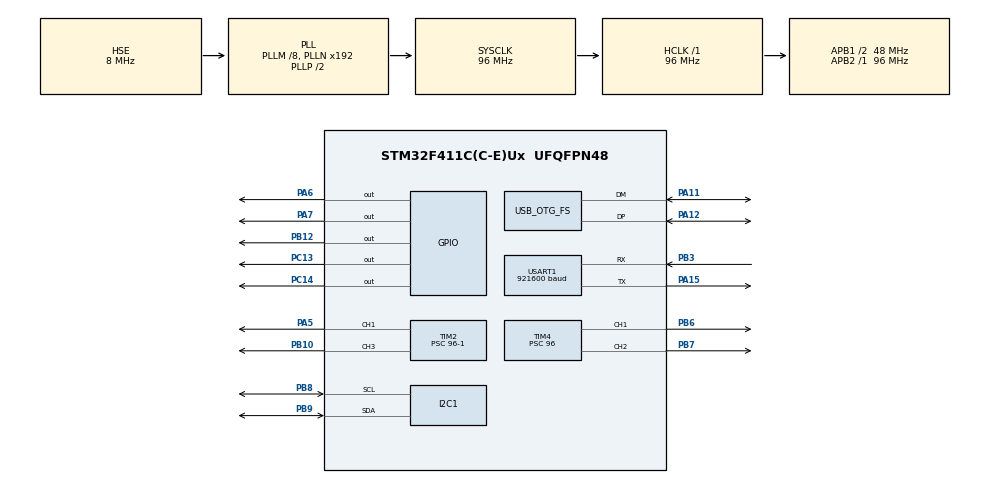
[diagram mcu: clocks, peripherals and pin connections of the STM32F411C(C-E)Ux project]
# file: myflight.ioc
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FREERTOS.Tasks01=defaultTask,8,128,StartDefaultTask,As weak,NULL,Dynamic,NULL,NULL;TaskSensorMotor,40,1024,StartTaskSensorMotor,As weak,NULL,Dynamic,NULL,NULL;TaskDebug,8,512,StartTaskDebug,As weak,NULL,Dynamic,NULL,NULL;TaskLED,8,512,StartTaskLED,As weak,NULL,Dynamic,NULL,NULL;TaskMessage,48,512,StartTaskMessage,As weak,NULL,Dynamic,NULL,NULL
FREERTOS.configENABLE_FPU=1
I2C1.I2C_Mode=I2C_Standard
Mcu.Family=STM32F4
Mcu.Name=STM32F411C(C-E)Ux
Mcu.Package=UFQFPN48
NVIC.OTG_FS_IRQn=true\:5\:0\:false\:false\:true\:true\:false\:true
NVIC.PriorityGroup=NVIC_PRIORITYGROUP_4
NVIC.TIM1_UP_TIM10_IRQn=true\:0\:0\:false\:false\:true\:false\:false\:true
NVIC.TimeBase=TIM1_UP_TIM10_IRQn
NVIC.TimeBaseIP=TIM10
NVIC.USART1_IRQn=true\:5\:0\:false\:false\:true\:true\:true\:true
PA11.Mode=Device_Only
PA11.Signal=USB_OTG_FS_DM
PA12.Mode=Device_Only
PA12.Signal=USB_OTG_FS_DP
PA15.Mode=Asynchronous
PA15.Signal=USART1_TX
PA5.Signal=S_TIM2_CH1_ETR
PA6.GPIO_ModeDefaultOutputPP=GPIO_MODE_OUTPUT_PP
PA6.GPIO_PuPd=GPIO_PULLDOWN
PA6.GPIO_Speed=GPIO_SPEED_FREQ_VERY_HIGH
PA6.PinState=GPIO_PIN_SET
PA6.Signal=GPIO_Output
PA7.GPIO_ModeDefaultOutputPP=GPIO_MODE_OUTPUT_PP
PA7.GPIO_PuPd=GPIO_PULLDOWN
PA7.GPIO_Speed=GPIO_SPEED_FREQ_VERY_HIGH
PA7.PinState=GPIO_PIN_SET
PA7.Signal=GPIO_Output
PB10.Signal=S_TIM2_CH3
PB12.GPIO_ModeDefaultOutputPP=GPIO_MODE_OUTPUT_PP
PB12.GPIO_PuPd=GPIO_PULLDOWN
PB12.GPIO_Speed=GPIO_SPEED_FREQ_VERY_HIGH
PB12.PinState=GPIO_PIN_RESET
PB12.Signal=GPIO_Output
PB3.Mode=Asynchronous
PB3.Signal=USART1_RX
PB6.Signal=S_TIM4_CH1
PB7.Signal=S_TIM4_CH2
PB8.Mode=I2C
PB8.Signal=I2C1_SCL
PB9.Mode=I2C
PB9.Signal=I2C1_SDA
PC13-ANTI_TAMP.GPIO_ModeDefaultOutputPP=GPIO_MODE_OUTPUT_PP
PC13-ANTI_TAMP.GPIO_PuPd=GPIO_PULLDOWN
PC13-ANTI_TAMP.PinState=GPIO_PIN_SET
PC13-ANTI_TAMP.Signal=GPIO_Output
PC14-OSC32_IN.GPIO_ModeDefaultOutputPP=GPIO_MODE_OUTPUT_PP
PC14-OSC32_IN.GPIO_PuPd=GPIO_PULLDOWN
PC14-OSC32_IN.PinState=GPIO_PIN_SET
PC14-OSC32_IN.Signal=GPIO_Output
PH0\ -\ OSC_IN.Mode=HSE-External-Oscillator
PH0\ -\ OSC_IN.Signal=RCC_OSC_IN
PH1\ -\ OSC_OUT.Mode=HSE-External-Oscillator
PH1\ -\ OSC_OUT.Signal=RCC_OSC_OUT
ProjectManager.HeapSize=0x3000
ProjectManager.StackSize=0x800
ProjectManager.TargetToolchain=MDK-ARM V5.27
RCC.48MHZClocksFreq_Value=48000000
RCC.AHBFreq_Value=96000000
RCC.APB1CLKDivider=RCC_HCLK_DIV2
RCC.APB1Freq_Value=48000000
RCC.APB1TimFreq_Value=96000000
RCC.APB2Freq_Value=96000000
RCC.APB2TimFreq_Value=96000000
RCC.CortexFreq_Value=96000000
RCC.HCLKFreq_Value=96000000
RCC.HSE_VALUE=8000000
RCC.HSI_VALUE=16000000
RCC.LSE_VALUE=32768
RCC.PLLM=8
RCC.SYSCLKFreq_VALUE=96000000
RCC.SYSCLKSource=RCC_SYSCLKSOURCE_PLLCLK
RCC.VCOOutputFreq_Value=192000000
SH.S_TIM2_CH1_ETR.0=TIM2_CH1,PWM Generation1 CH1
SH.S_TIM2_CH3.0=TIM2_CH3,PWM Generation3 CH3
SH.S_TIM4_CH1.0=TIM4_CH1,PWM Generation1 CH1
SH.S_TIM4_CH2.0=TIM4_CH2,PWM Generation2 CH2
TIM2.Channel-PWM\ Generation1\ CH1=TIM_CHANNEL_1
TIM2.Channel-PWM\ Generation3\ CH3=TIM_CHANNEL_3
TIM2.Period=1000
TIM2.Prescaler=96-1
TIM4.Channel-PWM\ Generation1\ CH1=TIM_CHANNEL_1
TIM4.Channel-PWM\ Generation2\ CH2=TIM_CHANNEL_2
TIM4.Period=1000
TIM4.Prescaler=96
USART1.BaudRate=921600
USART1.VirtualMode=VM_ASYNC
USB_DEVICE.CLASS_NAME_FS=CDC
USB_DEVICE.VirtualMode=Cdc
USB_DEVICE.VirtualModeFS=Cdc_FS
USB_OTG_FS.VirtualMode=Device_Only
VP_FREERTOS_VS_CMSIS_V2.Mode=CMSIS_V2
VP_SYS_VS_tim10.Mode=TIM10
VP_USB_DEVICE_VS_USB_DEVICE_CDC_FS.Mode=CDC_FS
board=custom

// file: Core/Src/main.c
/* USER CODE BEGIN Header */
/**
  ******************************************************************************
  * @file           : main.c
  * @brief          : Main program body
  ******************************************************************************
  * @attention
  *
  * <h2><center>&copy; Copyright (c) 2020 STMicroelectronics.
  * All rights reserved.</center></h2>
  *
  * This software component is licensed by ST under Ultimate Liberty license
  * SLA0044, the "License"; You may not use this file except in compliance with
  * the License. You may obtain a copy of the License at:
  *                             www.st.com/SLA0044
  *
  ******************************************************************************
  */
/* USER CODE END Header */

#include "main.h"
#include "cmsis_os.h"
#include "i2c.h"
#include "tim.h"
#include "usart.h"
#include "usb_device.h"
#include "gpio.h"

void SystemClock_Config(void);
void MX_FREERTOS_Init(void);

int main(void)
{

  /* MCU Configuration--------------------------------------------------------*/

  /* Reset of all peripherals, Initializes the Flash interface and the Systick. */
  HAL_Init();

  /* Configure the system clock */
  SystemClock_Config();

  /* Initialize all configured peripherals */
  MX_GPIO_Init();
  MX_I2C1_Init();
  MX_TIM2_Init();
  MX_TIM4_Init();
  MX_USART1_UART_Init();
  /* USER CODE BEGIN 2 */

    HAL_TIM_PWM_Start(&htim2, TIM_CHANNEL_1);
    HAL_TIM_PWM_Start(&htim2, TIM_CHANNEL_3);
    HAL_TIM_PWM_Start(&htim4, TIM_CHANNEL_1);
    HAL_TIM_PWM_Start(&htim4, TIM_CHANNEL_2);

  /* USER CODE END 2 */

  /* Init scheduler */
  osKernelInitialize();  /* Call init function for freertos objects (in freertos.c) */
  MX_FREERTOS_Init();
  /* Start scheduler */
  osKernelStart();

  /* We should never get here as control is now taken by the scheduler */
  /* Infinite loop */
  while (1)
  {

  }
}

void SystemClock_Config(void)
{
  RCC_OscInitTypeDef RCC_OscInitStruct = {0};
  RCC_ClkInitTypeDef RCC_ClkInitStruct = {0};

  /** Configure the main internal regulator output voltage
  */
  __HAL_RCC_PWR_CLK_ENABLE();
  __HAL_PWR_VOLTAGESCALING_CONFIG(PWR_REGULATOR_VOLTAGE_SCALE1);
  /** Initializes the CPU, AHB and APB busses clocks
  */
  RCC_OscInitStruct.OscillatorType = RCC_OSCILLATORTYPE_HSE;
  RCC_OscInitStruct.HSEState = RCC_HSE_ON;
  RCC_OscInitStruct.PLL.PLLState = RCC_PLL_ON;
  RCC_OscInitStruct.PLL.PLLSource = RCC_PLLSOURCE_HSE;
  RCC_OscInitStruct.PLL.PLLM = 8;
  RCC_OscInitStruct.PLL.PLLN = 192;
  RCC_OscInitStruct.PLL.PLLP = RCC_PLLP_DIV2;
  RCC_OscInitStruct.PLL.PLLQ = 4;
  if (HAL_RCC_OscConfig(&RCC_OscInitStruct) != HAL_OK)
  {
    Error_Handler();
  }
  /** Initializes the CPU, AHB and APB busses clocks
  */
  RCC_ClkInitStruct.ClockType = RCC_CLOCKTYPE_HCLK|RCC_CLOCKTYPE_SYSCLK
                              |RCC_CLOCKTYPE_PCLK1|RCC_CLOCKTYPE_PCLK2;
  RCC_ClkInitStruct.SYSCLKSource = RCC_SYSCLKSOURCE_PLLCLK;
  RCC_ClkInitStruct.AHBCLKDivider = RCC_SYSCLK_DIV1;
  RCC_ClkInitStruct.APB1CLKDivider = RCC_HCLK_DIV2;
  RCC_ClkInitStruct.APB2CLKDivider = RCC_HCLK_DIV1;

  if (HAL_RCC_ClockConfig(&RCC_ClkInitStruct, FLASH_LATENCY_3) != HAL_OK)
  {
    Error_Handler();
  }
}

 /**
  * @brief  Period elapsed callback in non blocking mode
  * @note   This function is called  when TIM10 interrupt took place, inside
  * HAL_TIM_IRQHandler(). It makes a direct call to HAL_IncTick() to increment
  * a global variable "uwTick" used as application time base.
  * @param  htim : TIM handle
  * @retval None
  */
void HAL_TIM_PeriodElapsedCallback(TIM_HandleTypeDef *htim)
{
  if (htim->Instance == TIM10) {
    HAL_IncTick();
  }
}

void Error_Handler(void)
{
}

/************************ (C) COPYRIGHT STMicroelectronics *****END OF FILE****/

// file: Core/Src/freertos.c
/* USER CODE BEGIN Header */
/**
  ******************************************************************************
  * File Name          : freertos.c
  * Description        : Code for freertos applications
  ******************************************************************************
  * @attention
  *
  * <h2><center>&copy; Copyright (c) 2020 STMicroelectronics.
  * All rights reserved.</center></h2>
  *
  * This software component is licensed by ST under Ultimate Liberty license
  * SLA0044, the "License"; You may not use this file except in compliance with
  * the License. You may obtain a copy of the License at:
  *                             www.st.com/SLA0044
  *
  ******************************************************************************
  */
/* USER CODE END Header */

#include "FreeRTOS.h"
#include "task.h"
#include "main.h"
#include "cmsis_os.h"

/* Definitions for defaultTask */
osThreadId_t defaultTaskHandle;
const osThreadAttr_t defaultTask_attributes = {
  .name = "defaultTask",
  .priority = (osPriority_t) osPriorityLow,
  .stack_size = 128 * 4
};
/* Definitions for TaskSensorMotor */
osThreadId_t TaskSensorMotorHandle;
const osThreadAttr_t TaskSensorMotor_attributes = {
  .name = "TaskSensorMotor",
  .priority = (osPriority_t) osPriorityHigh,
  .stack_size = 1024 * 4
};
/* Definitions for TaskDebug */
osThreadId_t TaskDebugHandle;
const osThreadAttr_t TaskDebug_attributes = {
  .name = "TaskDebug",
  .priority = (osPriority_t) osPriorityLow,
  .stack_size = 512 * 4
};
/* Definitions for TaskLED */
osThreadId_t TaskLEDHandle;
const osThreadAttr_t TaskLED_attributes = {
  .name = "TaskLED",
  .priority = (osPriority_t) osPriorityLow,
  .stack_size = 512 * 4
};
/* Definitions for TaskMessage */
osThreadId_t TaskMessageHandle;
const osThreadAttr_t TaskMessage_attributes = {
  .name = "TaskMessage",
  .priority = (osPriority_t) osPriorityRealtime,
  .stack_size = 512 * 4
};

void StartDefaultTask(void *argument);
void StartTaskSensorMotor(void *argument);
void StartTaskDebug(void *argument);
void StartTaskLED(void *argument);
void StartTaskMessage(void *argument);

extern void MX_USB_DEVICE_Init(void);
void MX_FREERTOS_Init(void); /* (MISRA C 2004 rule 8.1) */

void MX_FREERTOS_Init(void) {

  /* Create the thread(s) */
  /* creation of defaultTask */
  defaultTaskHandle = osThreadNew(StartDefaultTask, NULL, &defaultTask_attributes);

  /* creation of TaskSensorMotor */
  TaskSensorMotorHandle = osThreadNew(StartTaskSensorMotor, NULL, &TaskSensorMotor_attributes);

  /* creation of TaskDebug */
  TaskDebugHandle = osThreadNew(StartTaskDebug, NULL, &TaskDebug_attributes);

  /* creation of TaskLED */
  TaskLEDHandle = osThreadNew(StartTaskLED, NULL, &TaskLED_attributes);

  /* creation of TaskMessage */
  TaskMessageHandle = osThreadNew(StartTaskMessage, NULL, &TaskMessage_attributes);

}

__weak void StartDefaultTask(void *argument)
{
  /* init code for USB_DEVICE */
  MX_USB_DEVICE_Init();
  /* USER CODE BEGIN StartDefaultTask */
    osThreadTerminate(defaultTaskHandle);
  /* Infinite loop */
  for(;;)
  {
    osDelay(1);
  }
  /* USER CODE END StartDefaultTask */
}

__weak void StartTaskSensorMotor(void *argument)
{
  for(;;)
  {
    osDelay(1);
  }
}

__weak void StartTaskDebug(void *argument)
{
  for(;;)
  {
    osDelay(1);
  }
}

__weak void StartTaskLED(void *argument)
{
  for(;;)
  {
    osDelay(1);
  }
}

__weak void StartTaskMessage(void *argument)
{
  for(;;)
  {
    osDelay(1);
  }
}

/************************ (C) COPYRIGHT STMicroelectronics *****END OF FILE****/
